# Template register map
Vendor: VendorName Co.Ltd; Series: SeriesName; File version: 1.2
CPU: CM7 r0p1, little endian, MPU, FPU, 4 interrupt priority bits
Registers are 32-bit, read-write, no defined reset value unless marked. A register's access mark holds for its fields unless they carry their own. Offsets are from the block's base; [hi:lo] are bit positions; lines under a group give offsets from that group; {n}, {i} and the like mark numbered series.

## TIM1 — Advanced-Control Timer 1
Base 0x4004A000
Same registers: TIM2 0x4004B000
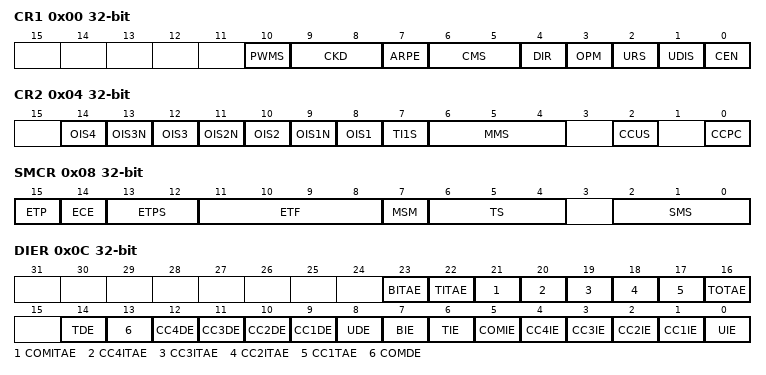
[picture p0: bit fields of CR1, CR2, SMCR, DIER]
0x00 CR1 — TIM control register 1
  [10] PWMS — TIM PWMS bit: PWM mode select
  [9:8] CKD — TIM CKD[1:0] bit: clock division
  [7] ARPE — TIM ARPE bit: auto-reload preload enable
  [6:5] CMS — TIM CMS[1:0] bit: center-aligned mode selection
  [4] DIR — TIM DIR bit: count direction
  [3] OPM — TIM OPM bit: one pulse mode
  [2] URS — TIM URS bit: update request source
  [1] UDIS — TIM UDIS bit: update disable
  [0] CEN — TIM CEN bit: counter enable
0x04 CR2 — TIM control register 2
  [2n+6] OIS{n} (n=1..4) — TIM OIS{n} bit: OIS{n} output idle state
  [13] OIS3N — TIM OIS3N bit: OIS3N output idle state
  [11] OIS2N — TIM OIS2N bit: OIS2N output idle state
  [9] OIS1N — TIM OIS1N bit: OIS1N output idle state
  [7] TI1S — TIM TI1S bit: TI1 selection
  [6:4] MMS — TIM MMS[2:0] bit: master mode selection
  [2] CCUS — TIM CCUS bit: capture or compare control update selection
  [0] CCPC — TIM CCPC bit: capture or compare preloaded control
0x08 SMCR — TIM slave mode control register
  [15] ETP — TIM ETP bit: external trigger polarity
  [14] ECE — TIM ECE bit: external clock enable
  [13:12] ETPS — TIM ETPS[1:0] bit: external trigger prescaler
  [11:8] ETF — TIM ETF[3:0] bit: external trigger filter
  [7] MSM — TIM MSM bit: master or slave mode
  [6:4] TS — TIM TS[2:0] bit: trigger selection
  [2:0] SMS — TIM SMS[2:0] bit: slave mode selection
0x0C DIER — TIM interrupt enable register
  [23] BITAE — TIM BITAE bit: break interrupt triger ADC enable
  [22] TITAE — TIM TITAE bit: trigger interrupt triger ADC enable
  [21] COMITAE — TIM COMITAE bit: COM interrupt triger ADC enable
  [20] CC4ITAE — TIM CC4ITAE bit: capture or compare 4 interrupt triger ADC enable
  [19] CC3ITAE — TIM CC3ITAE bit: capture or compare 3 interrupt triger ADC enable
  [18] CC2ITAE — TIM CC2ITAE bit: capture or compare 2 interrupt triger ADC enable
  [17] CC1TAE — TIM CC1TAE bit: capture or compare 1 interrupt triger ADC enable
  [16] TOTAE — TIM TOTAE bit: TRGO trigger ADC enable
  [14] TDE — TIM TDE bit: trigger DMA request enable
  [13] COMDE — TIM COMDE bit: COM DMA request enable
  [n+8] CC{n}DE (n=1..4) — TIM CC{n}DE bit: capture or compare {n} DMA request enable
  [8] UDE — TIM UDE bit: update DMA request enable
  [7] BIE — TIM BIE bit: break interrupt enable
  [6] TIE — TIM TIE bit: trigger interrupt enable
  [5] COMIE — TIM COMIE bit: COM interrupt enable
  [n] CC{n}IE (n=1..4) — TIM CC{n}IE bit: capture or compare {n} interrupt enable
  [0] UIE — TIM UIE bit: update interrupt enable
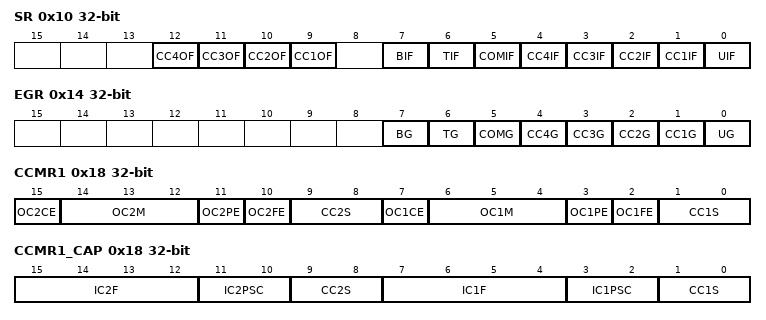
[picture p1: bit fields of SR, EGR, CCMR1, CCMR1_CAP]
0x10 SR — TIM state register
  [n+8] CC{n}OF (n=1..4) — TIM CC{n}OF bit: capture or compare {n} overcapture flag
  [7] BIF — TIM BIF bit: break interrupt flag
  [6] TIF — TIM TIF bit: trigger interrupt flag
  [5] COMIF — TIM COMIF bit: COM interrupt flag
  [n] CC{n}IF (n=1..4) — TIM CC{n}IF bit: capture or compare {n} interrupt flag
  [0] UIF — TIM UIF bit: update interrupt flag
0x14 EGR wo — TIM event trigger register
  [7] BG — TIM BG bit: break generation
  [6] TG — TIM TG bit: trigger generation
  [5] COMG — TIM COMG bit: capture or compare control update generation
  [n] CC{n}G (n=1..4) — TIM CC{n}G bit: capture or compare {n} generation
  [0] UG — TIM UG bit: update generation
0x18 CCMR1 — TIM capture/compare mode register 1
  [15] OC2CE — TIM OC2CE bit: output compare 2 clear enable
  [14:12] OC2M — TIM OC2M[2:0] bit: output compare 2 mode
  [11] OC2PE — TIM OC2PE bit: output compare 2 preload enable
  [10] OC2FE — TIM OC2FE bit: output compare 2 fast enable
  [9:8] CC2S — TIM CC2S[1:0] bit: capture or compare 2 selection
  [7] OC1CE — TIM OC1CE bit: output compare 1 clear enable
  [6:4] OC1M — TIM OC1M[2:0] bit: output compare 1 mode
  [3] OC1PE — TIM OC1PE bit: output compare 1 preload enable
  [2] OC1FE — TIM OC1FE bit: output compare 1 fast enable
  [1:0] CC1S — TIM CC1S[1:0] bit: capture or compare 1 selection
0x18 CCMR1_CAP (alternate view of CCMR1) — TIM capture/compare mode register 1
  [15:12] IC2F — TIM IC2F[3:0] bit: input capture 2 filter
  [11:10] IC2PSC — TIM IC2PSC[1:0] bit: input capture 2 prescaler
  [9:8] CC2S — TIM CC2S[1:0] bit: capture or compare 2 selection
  [7:4] IC1F — TIM IC1F[3:0] bit: input capture 1 filter
  [3:2] IC1PSC — TIM IC1PSC[1:0] bit: input capture 1 prescaler
  [1:0] CC1S — TIM CC1S[1:0] bit: capture or compare 1 selection
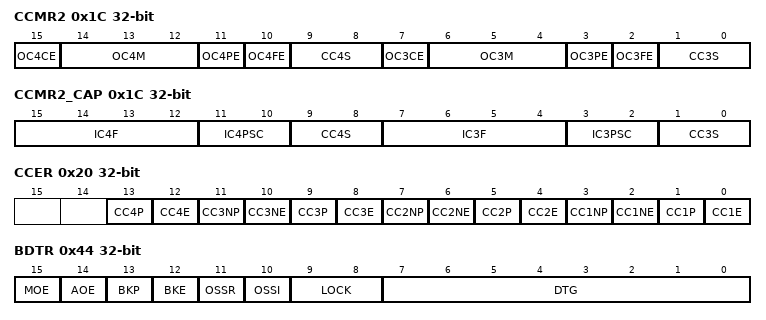
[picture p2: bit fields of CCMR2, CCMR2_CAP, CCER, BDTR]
0x1C CCMR2 — TIM capture/compare mode register 2
  [15] OC4CE — TIM OC4CE bit: output compare 4 clear enable
  [14:12] OC4M — TIM OC4M[2:0] bit: output compare 4 mode
  [11] OC4PE — TIM OC4PE bit: output compare 4 preload enable
  [10] OC4FE — TIM OC4FE bit: output compare 4 fast enable
  [9:8] CC4S — TIM CC4S[1:0] bit: capture or compare 4 selection
  [7] OC3CE — TIM OC3CE bit: output compare 3 clear enable
  [6:4] OC3M — TIM OC3M[2:0] bit: output compare 3 mode
  [3] OC3PE — TIM OC3PE bit: output compare 3 preload enable
  [2] OC3FE — TIM OC3FE bit: output compare 3 fast enable
  [1:0] CC3S — TIM CC3S[1:0] bit: capture or compare 3 selection
0x1C CCMR2_CAP (alternate view of CCMR2) — TIM capture/compare mode register 2
  [15:12] IC4F — TIM IC4F[3:0] bit: input capture 4 filter
  [11:10] IC4PSC — TIM IC4PSC[1:0] bit: input capture 4 prescaler
  [9:8] CC4S — TIM CC4S[1:0] bit: capture or compare 4 selection
  [7:4] IC3F — TIM IC3F[3:0] bit: input capture 3 filter
  [3:2] IC3PSC — TIM IC3PSC[1:0] bit: input capture 3 prescaler
  [1:0] CC3S — TIM CC3S[1:0] bit: capture or compare 3 selection
0x20 CCER — TIM capture/compare enable register
  [4n-3] CC{n}P (n=1..4) — TIM CC{n}P bit: capture or compare {n} output polarity
  [4n-4] CC{n}E (n=1..4) — TIM CC{n}E bit: capture or compare {n} output enable
  [11] CC3NP — TIM CC3NP bit: capture or compare 3 complementary output polarity
  [10] CC3NE — TIM CC3NE bit: capture or compare 3 complementary output enable
  [7] CC2NP — TIM CC2NP bit: capture or compare 2 complementary output polarity
  [6] CC2NE — TIM CC2NE bit: capture or compare 2 complementary output enable
  [3] CC1NP — TIM CC1NP bit: capture or compare 1 complementary output polarity
  [2] CC1NE — TIM CC1NE bit: capture or compare 1 complementary output enable
0x24 CNT — TIM counter register
  [15:0] CNT — TIM CNT[15:0] bit: counter value
0x28 PSC — TIM prescaler register
  [15:0] PSC — TIM PSC[15:0] bit: prescaler value
0x2C ARR — TIM auto reload register
  [15:0] ARR — TIM ARR[15:0] bit: auto-reload value
0x30 RCR — TIM repeat counter register
  [7:0] REP — TIM REP[7:0] bit: repetition counter value
{0x30+4i} CCR{i}A (i=1..4) — TIM capture/compare with group A register {i}
  [15:0] CCR{i}A — TIM CCR{i}A[15:0] bit: capture or compare {i} value
0x44 BDTR — TIM break deadtime register
  [15] MOE — TIM MOE bit: main output enable
  [14] AOE — TIM AOE bit: automatic output enable
  [13] BKP — TIM BKP bit: break polarity
  [12] BKE — TIM BKE bit: break enable
  [11] OSSR — TIM OSSR bit: off-state selection for run mode
  [10] OSSI — TIM OSSI bit: off-state selection for Idle mode
  [9:8] LOCK — TIM LOCK[1:0] bit: lock configuration
  [7:0] DTG — TIM DTG[7:0] bit: dead-time generator setup
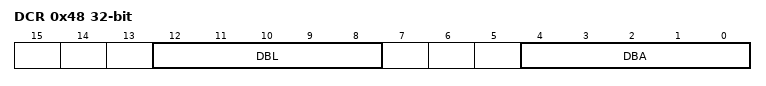
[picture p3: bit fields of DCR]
0x48 DCR — TIM DMA control register
  [12:8] DBL — TIM DBL[4:0] bit: DMA burst length
  [4:0] DBA — TIM DBA[4:0] bit: DMA base address
0x4C DMAR — TIM DMA address register
  [31:0] DMAB — TIM DMAB[31:0] bit: DMA register for burst accesses
{0x4C+4i} CCR{i}B (i=1..4) — TIM capture/compare with group B register {i}
  [15:0] CCR{i}B — TIM CCR{i}B[15:0] bit: compare {i} value
